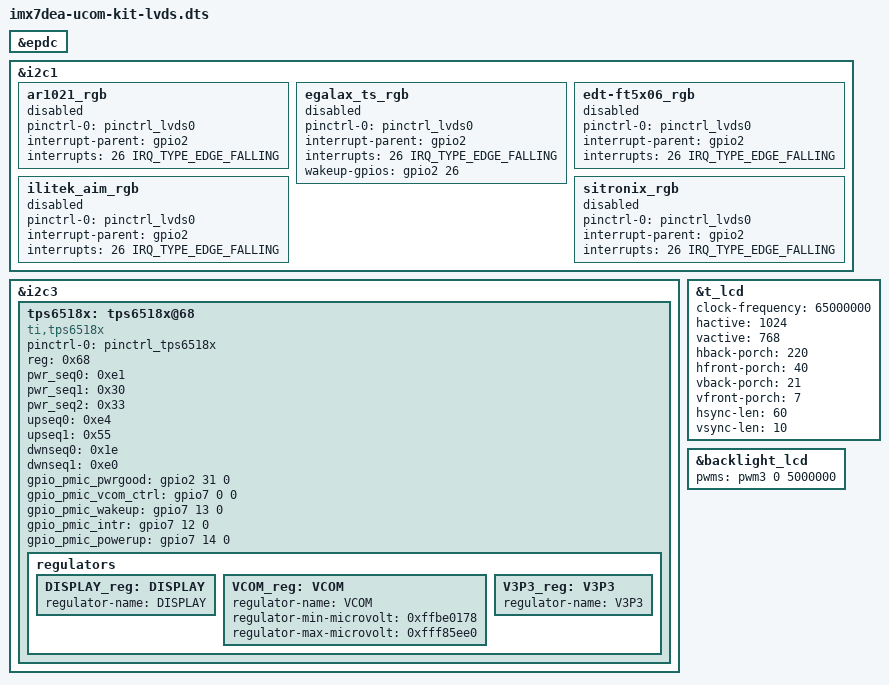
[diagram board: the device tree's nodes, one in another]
/*
 * Copyright (C) 2014-2015 Freescale Semiconductor, Inc.
 *
 * This program is free software; you can redistribute it and/or modify
 * it under the terms of the GNU General Public License version 2 as
 * published by the Free Software Foundation.
 */

#include "imx7dea-ucom-kit.dts"



/*
 * Change settings to match the NXP/Freescale LVDS display connected
 * to the RGB-to-LVDS bridge on the uCOM Adapter Board. The touch
 * controller settings (ar1021 and egalax) and the timing0 values
 * should be handled by the eadisp/eatouch command and not here.
 * The backlight pin must be change from PWM1 (used by RGB) to PWM3
 * when using LVDS.
 */

&epdc {
        status = "okay";
};

&i2c1 {
    ar1021_rgb {
	pinctrl-0 = <&pinctrl_lvds0>;
	interrupt-parent = <&gpio2>;
	interrupts = <26 IRQ_TYPE_EDGE_FALLING>;
	status = "disabled";
    };

    egalax_ts_rgb {
	pinctrl-0 = <&pinctrl_lvds0>;
	interrupt-parent = <&gpio2>;
	interrupts = <26 IRQ_TYPE_EDGE_FALLING>;
	wakeup-gpios = <&gpio2 26 GPIO_ACTIVE_HIGH>;
	status = "disabled";
    };

    edt-ft5x06_rgb {
	pinctrl-0 = <&pinctrl_lvds0>;
	interrupt-parent = <&gpio2>;
	interrupts = <26 IRQ_TYPE_EDGE_FALLING>;
	status = "disabled";
    };

    ilitek_aim_rgb {
	pinctrl-0 = <&pinctrl_lvds0>;
	interrupt-parent = <&gpio2>;
	interrupts = <26 IRQ_TYPE_EDGE_FALLING>;
	status = "disabled";
    };

    sitronix_rgb {
	pinctrl-0 = <&pinctrl_lvds0>;
	interrupt-parent = <&gpio2>;
	interrupts = <26 IRQ_TYPE_EDGE_FALLING>;
	status = "disabled";
    };
};

&i2c3 {
	tps6518x: tps6518x@68 {
		pinctrl-names = "default";
		pinctrl-0 = <&pinctrl_tps6518x>;
		compatible = "ti,tps6518x";
		reg = <0x68>;
		status = "okay";
	
		/*
		* power sequencing for TPS65180/65181
		*/		 
		pwr_seq0 = <0xe1>; /* [Vddh-seq=3 | Vpos-seq=2 | Vee-seq=0 | Vneg-seq=1] */
		pwr_seq1 = <0x30>; /* [Vneg-dly1=3 |Vee-dly0=0]  mSec */
		pwr_seq2 = <0x33>; /* [Vddh-dly3=3 | Vpos-dly2=3] mSec */
		/*
		 * power sequencing for TPS65185/65186
		 */
		upseq0 = <0xe4>;
		upseq1 = <0x55>;
		dwnseq0 = <0x1e>;
		dwnseq1 = <0xe0>;
				

		gpio_pmic_pwrgood = <&gpio2 31 0>;	//<&gpio2 31 0>; //las mismas variables se llaman desde el device driver
		gpio_pmic_vcom_ctrl = <&gpio7 0 0>; //<&gpio4 14 0>;
		gpio_pmic_wakeup = <&gpio7 13 0>; //<&gpio2 23 0>;
		gpio_pmic_intr = <&gpio7 12 0>;
		gpio_pmic_powerup = <&gpio7 14 0>;

		regulators {
			DISPLAY_reg: DISPLAY {
				regulator-name = "DISPLAY";
			};


			VCOM_reg: VCOM {
				regulator-name = "VCOM";
				/* 2's-compliment, -4325000 */
				regulator-min-microvolt = <0xffbe0178>;
				/* 2's-compliment, -500000 */
				regulator-max-microvolt = <0xfff85ee0>;
			};

			V3P3_reg: V3P3 {
				regulator-name = "V3P3";
			};
		};
	};
};

&t_lcd {
	clock-frequency = <65000000>;
        hactive = <1024>;
        vactive = <768>;
		hback-porch = <220>;
		hfront-porch = <40>;
		vback-porch = <21>;
		vfront-porch = <7>;
		hsync-len = <60>;
		vsync-len = <10>;
};

&backlight_lcd {
	pwms = <&pwm3 0 5000000>;
};


